# LCM32F039 register map
File version: 1.0
CPU: CM0 r1p0, little endian, MPU, no FPU, 3 interrupt priority bits
Registers are 32-bit, read-write, reset 0x0 unless marked. A register's access mark holds for its fields unless they carry their own. Offsets are from the block's base; lines under a group give offsets from that group; [hi:lo] are bit positions; {n}, {i} and the like mark numbered series; 'fields as' and 'values as' point back to an identical list; <NAME> marks a mode.

## Memory map
0x40000000 UART3 size 0x1000
0x40006000 SPI2 size 0x1000
0x40008000 LCD size 0x1000 — liquid crystal display
0x4000A000 TIM14 size 0x1000 — General timer
0x4000B000 TIM3 size 0x1000 — General timer
0x4000D000 WWDG size 0x1000
0x40010000 TIM1 size 0x1000 — Advanced timer
0x40011000 EXTI size 0x1000
0x40013000 I2C0 size 0x1000 — I2C communication interface
0x40014000 UART0 size 0x1000 — Universal asynchronous receiver transmitter
0x40015000 UART1 size 0x1000
0x40017000 CHIPCTRL size 0x400 — chip controler moudle.
0x40017400 IWDG size 0x400
0x40017800 WT size 0x400
0x40017C00 ANACTRL size 0x400 — Analog system controler.
0x40018000 SPI0 size 0x1000 — ARM PrimeCell SSP (PL022)
0x4001A000 ADC size 0x1000
0x4001B000 TIM15 size 0x1000 — General timer
0x4001C000 TIM16 size 0x1000 — General timer
0x4001D000 FLASH size 0x1000 — eflash controller
0x4001E000 TIM17 size 0x1000
0x4001F000 TIM2 size 0x1000 — General timer
0x48000000 GPIOA size 0x200
0x48000200 GPIOB size 0x200
0x48000400 GPIOC size 0x200
0x48000A00 GPIOF size 0x200 — General-purpose I/Os
0x48004000 DMAC size 0x1000 — DMA control moudle
0x48007000 SYSCTRL size 0x1000
0x48011000 CRC size 0x1000
0x48014000 DIV size 0x1000

## Interrupts
2 WT — WT ISR
3 EFLS (FLASH) — falsh controller interrupt.
4 CHIPCTRL — CHIPCTRL_Handler().
5 EXTI0_1 (EXTI) — exti line from 0 to 1.
6 EXTI2_3 (EXTI) — exti line from 2 to 3.
7 EXTI4_15 (EXTI) — exti line from 4 to 15.
8 EXTI19_21 (LCD, EXTI) — falsh controller interrupt.
9 DMAC_CH0 (DMAC) — DMAC_CH0 ISR
10 DMAC_CH1_2 (DMAC) — DMAC_CH1_2 ISR
11 DMAC_CH3 (DMAC) — DMAC_CH3 ISR
12 ADC — ADC_Handler()
13 TIM1_NON_CC (TIM1) — timer1 non capture compare
14 TIM1_CC (TIM1) — timer1 capture compare
15 TIM2 — tim2 interrupt
16 TIM3 — tim3 interrupt
19 TIM14 — tim14 interrupt
20 TIM15 — tim15 interrupt
21 TIM16 — tim16 interrupt
22 TIM17 — tim17 interrupt
23 I2C0 — I2C0 Interrupt vector
25 SPI0 — SPI0 interrupt
26 SPI2 — SPI2 ISR
27 UART0 — UART0 Interrupt vector
28 UART1 — uart1 interrupt
29 UART3 — uart3 interrupt
30 IWDG — IWDG Interrupt vector
31 DIV — DIV_Handler()

## UART0 — Universal asynchronous receiver transmitter
Base 0x40014000
Same registers: UART3 0x40000000, UART1 0x40015000
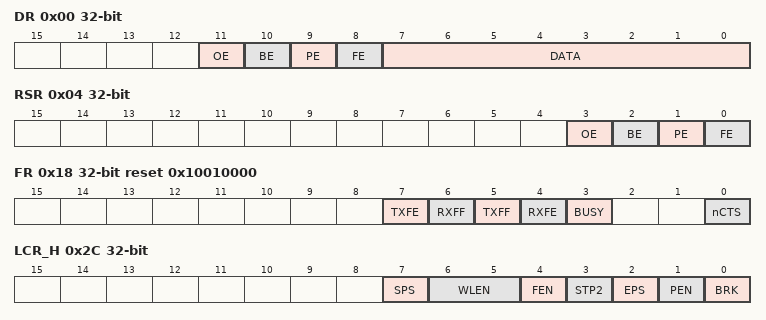
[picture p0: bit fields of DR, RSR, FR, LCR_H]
0x00 DR — Data Register
  [11] OE — Overrun error
  [10] BE — Break error
  [9] PE — Parity error
  [8] FE — Framing error.
  [7:0] DATA — Receive OR Transmit data character
0x04 RSR — Receive Status Register/Error Clear Register
  [3] OE — Overrun error
  [2] BE — Break error
  [1] PE — Parity error
  [0] FE — Framing error.
0x18 FR reset 0x10010000 — Flag Register
  [7] TXFE — Transmit FIFO empty
  [6] RXFF — Receive FIFO full
  [5] TXFF — Transmit FIFO full
  [4] RXFE — Receive FIFO empty
  [3] BUSY — UART busy
  [0] nCTS — Clear to send
0x24 IBRD — Integer Baud Rate Register
  [14:0] BAUD_DIVINT — The integer baud rate divisor.
0x28 FBRD — Fractional Baud Rate Register
  [5:0] BAUD_DIVFRAC — The fractional baud rate divisor.
0x2C LCR_H — Line Control Register
  [7] SPS — Stick parity select
  [6:5] WLEN — Word length.
  [4] FEN — Enable FIFOs
  [3] STP2 — Two stop bits select
  [2] EPS — Even parity select
  [1] PEN — Parity enable
  [0] BRK — Send break
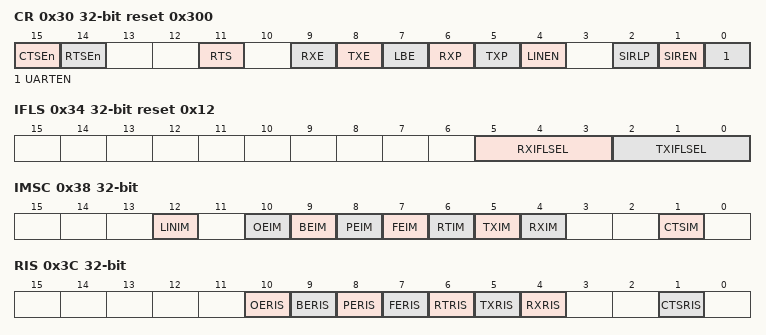
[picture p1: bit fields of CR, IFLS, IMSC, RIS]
0x30 CR reset 0x300 — Control Register
  [15] CTSEn — CTS hardware flow control enable
  [14] RTSEn — RTS hardware flow control enable
  [11] RTS — Request to send
  [9] RXE — Receive enable.
  [8] TXE — Transmit enable
  [7] LBE — Loopback enable
  [6] RXP — Loopback enable
  [5] TXP — Loopback enable
  [4] LINEN — Loopback enable
  [2] SIRLP — Loopback enable
  [1] SIREN — Loopback enable
  [0] UARTEN — UART enable
0x34 IFLS reset 0x12 — Interrupt FIFO Level Select Register
  [5:3] RXIFLSEL — Receive interrupt FIFO level select
  [2:0] TXIFLSEL — Transmit interrupt FIFO level select. T
0x38 IMSC — Interrupt Mask Set/Clear Register
  [12] LINIM — Overrun error interrupt mask.
  [10] OEIM — Overrun error interrupt mask.
  [9] BEIM — Break error interrupt mask
  [8] PEIM — Parity error interrupt mask.
  [7] FEIM — Framing error interrupt mask.
  [6] RTIM — Receive timeout interrupt mask
  [5] TXIM — Transmit interrupt mask.
  [4] RXIM — Receive interrupt mask.
  [1] CTSIM — nUARTCTS modem interrupt mask.
0x3C RIS ro — Raw Interrupt Status Register
  [10] OERIS — Overrun error interrupt status
  [9] BERIS — Break error interrupt mask
  [8] PERIS — Parity error interrupt status.
  [7] FERIS — Framing error interrupt status
  [6] RTRIS — Receive timeout interrupt status
  [5] TXRIS — Transmit interrupt status
  [4] RXRIS — Receive interrupt status
  [1] CTSRIS — nUARTCTS modem interrupt status.
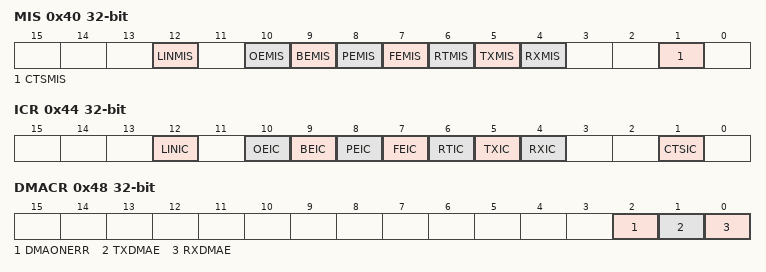
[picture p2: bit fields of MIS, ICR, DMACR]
0x40 MIS ro — Masked Interrupt Status Register
  [12] LINMIS — Overrun error masked interrupt status.
  [10] OEMIS — Overrun error masked interrupt status.
  [9] BEMIS — Break error masked interrupt status
  [8] PEMIS — Parity error masked interrupt status
  [7] FEMIS — Framing error masked interrupt status
  [6] RTMIS — Receive timeout masked interrupt status.
  [5] TXMIS — Transmit masked interrupt status
  [4] RXMIS — Receive masked interrupt status.
  [1] CTSMIS — nUARTCTS modem masked interrupt status
0x44 ICR — Interrupt Clear Register
  [12] LINIC — Overrun error interrupt clear
  [10] OEIC — Overrun error interrupt clear
  [9] BEIC — Break error interrupt clear
  [8] PEIC
  [7] FEIC — Framing error interrupt clear.
  [6] RTIC — Receive timeout interrupt clear
  [5] TXIC — Transmit interrupt clear.
  [4] RXIC — Receive interrupt clear
  [1] CTSIC — nUARTCTS modem interrupt clear
0x48 DMACR — DMA Control Register
  [2] DMAONERR — DMA on error.
  [1] TXDMAE — Transmit DMA enable
  [0] RXDMAE — Receive DMA enable
